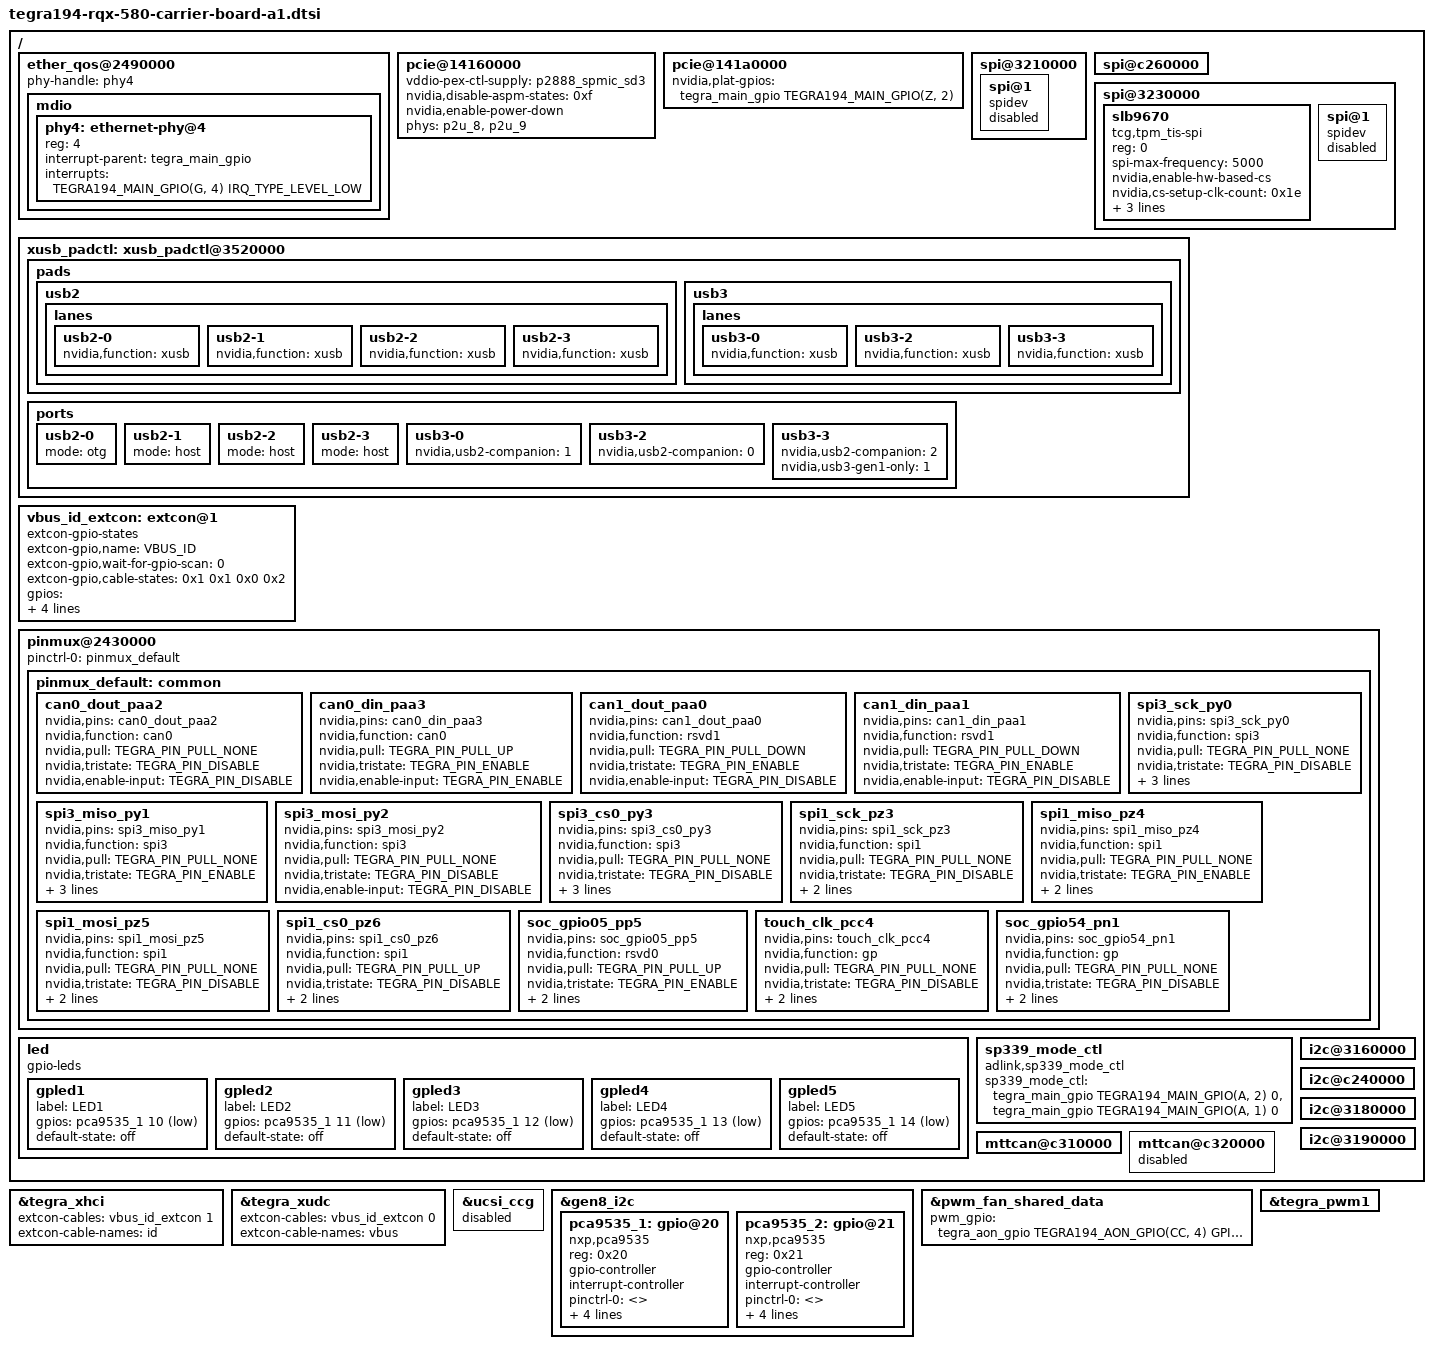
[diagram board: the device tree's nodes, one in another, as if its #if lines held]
/*
 * Copyright (c) 2020, ADLINKTECH CORPORATION.  All rights reserved.
 *
 * This program is free software; you can redistribute it and/or modify
 * it under the terms of the GNU General Public License as published by
 * the Free Software Foundation; version 2 of the License.
 *
 * This program is distributed in the hope that it will be useful, but WITHOUT
 * ANY WARRANTY; without even the implied warranty of MERCHANTABILITY or
 * FITNESS FOR A PARTICULAR PURPOSE.  See the GNU General Public License for
 * more details.
 */

#include <dt-bindings/gpio/tegra194-gpio.h>

/
{
    /* Etherent */
    ether_qos@2490000 {
		phy-handle = <&phy4>;
        mdio {
            phy4: ethernet-phy@4 {
				reg = <4>;
				interrupt-parent = <&tegra_main_gpio>;
				interrupts = <TEGRA194_MAIN_GPIO(G, 4) IRQ_TYPE_LEVEL_LOW>;				
			};
        };
    };

    /* <----- PCIE ----->  */
    pcie@14160000 { 
        status = "okay";

        vddio-pex-ctl-supply = <&p2888_spmic_sd3>;
        nvidia,disable-aspm-states = <0xf>;
        nvidia,enable-power-down;

        phys = <&p2u_8>, <&p2u_9>;
        phy-names = "pcie-p2u-0", "pcie-p2u-1";
    };
    
    //PCIe x16
    pcie@141a0000 { 
        status = "okay";

        nvidia,plat-gpios =
            <&tegra_main_gpio TEGRA194_MAIN_GPIO(Z, 2) GPIO_ACTIVE_HIGH    /* 3V3 */
               /*&tegra_main_gpio TEGRA194_MAIN_GPIO(A, 1) GPIO_ACTIVE_LOW  */ /* 12V */
            /*&tegra_main_gpio TEGRA194_MAIN_GPIO(Y, 4) GPIO_ACTIVE_HIGH */ /* I2C */
            >;
            //nvidia,disable-clock-request;
    };


    /* <----- SPI ----->  */
        // spi0
    spi@3210000 {
        status = "okay";
#if 0
        spi1_test: spi1_test@0 {  
            compatible = "spidev";
            reg = <0x0>;
            spi-max-frequency = <0x1312D00>;             
            status = "okay";
        };
#endif
            // spi0 CS.0 defined in : tegra194-p2888-0001-p2822-0000-common.dtsi
        /* SPI0 CS.1 */
        spi@1 {
            compatible = "spidev";
            status = "disabled";
        };
    };

    // spi1
    spi@c260000 {
        status = "okay";
    };

    // spi2
    spi@3230000 {
        status = "okay";
        slb9670: slb9670{   
            compatible = "tcg,tpm_tis-spi";
            reg = <0>; 
            #address-cells = <1>; 
            #size-cells = <0>; 
            spi-max-frequency = <5000>; 
            nvidia,enable-hw-based-cs;
            nvidia,cs-setup-clk-count = <0x1e>;
            nvidia,cs-hold-clk-count = <0x1e>;
            nvidia,rx-clk-tap-delay = <0x1f>;
            nvidia,tx-clk-tap-delau = <0x0>;
            status = "okay"; 
        };
        spi@1 {
            compatible = "spidev";
            status = "disabled";
        };
    };


#if TEGRA_XUSB_PADCONTROL_VERSION >= DT_VERSION_2

    xusb_padctl: xusb_padctl@3520000 {
        status = "okay";

        pads {
            usb2 {
                lanes {
                    usb2-0 {
                        nvidia,function = "xusb";
                        status = "okay";
                    };
                    usb2-1 {
                        nvidia,function = "xusb";
                        status = "okay";
                    };
                    usb2-2 {
                        nvidia,function = "xusb";
                        status = "okay";
                    };
                    usb2-3 {
                        nvidia,function = "xusb";
                        status = "okay";
                    };
                };
            };
            usb3 {
                lanes {
                    usb3-0 {
                            nvidia,function = "xusb";
                            status = "okay";
                    };
                    usb3-2 {
                            nvidia,function = "xusb";
                            status = "okay";
                    };
                    usb3-3 {
                            nvidia,function = "xusb";
                            status = "okay";
                    };
                };
            };
        };

        ports {
            usb2-0 {
                mode = "otg";
                status = "okay";
            };
            usb2-1 {
                mode = "host";
                status = "okay";
            };
            usb2-2 {
                mode = "host";
                status = "okay";
            };
            usb2-3 {
                mode = "host";
                status = "okay";
            };
            usb3-0 {
                nvidia,usb2-companion = <1>;
                status = "okay";
            };
            usb3-2 {
                nvidia,usb2-companion = <0>;
                status = "okay";
            };
            usb3-3 {
                nvidia,usb2-companion = <2>;
                nvidia,usb3-gen1-only= <1>;
                status = "okay";
            };
        };
    };
#endif

        vbus_id_extcon: extcon@1 { 
        compatible = "extcon-gpio-states";
        extcon-gpio,name = "VBUS_ID";
        extcon-gpio,wait-for-gpio-scan = <0>;

        extcon-gpio,cable-states = <0x1 0x1
                                    0x0 0x2>;
        gpios = <&tegra_main_gpio TEGRA194_MAIN_GPIO(Q, 0) 0>;
                        
#ifdef USE_VDD_5V_SATA
        vdd_5v_sata-supply = <&p2822_vdd_5v_sata>;
#endif
        //pin A62 for vbus detect pin and pin B55 for usb id pin

        /*
        extcon-gpio,cable-states = <0x3 0x0
                                    0x0 0x2
                                    0x1 0x2
                                    0x2 0x1>;
        gpios = <&tegra_aon_gpio TEGRA194_AON_GPIO(BB, 2) 0 
                 &tegra_main_gpio TEGRA194_MAIN_GPIO(Q, 0) 0>;
        */
        //extcon.h, EXTCON_NONE=0, EXTCON_USB=1, EXTCON_USB_HOST=2, 2019/04/24, Evan
        extcon-gpio,out-cable-names = <EXTCON_USB EXTCON_USB_HOST EXTCON_NONE>;
        #extcon-cells = <1>;
    };


    // pinmux for CAN0
    pinmux@2430000 {
        pinctrl-names = "default";
        pinctrl-0 = <&pinmux_default>;

        pinmux_default: common {
            /* <----- CAN pinmux ----->  */
            can0_dout_paa2 {
                nvidia,pins = "can0_dout_paa2";
                nvidia,function = "can0";
                nvidia,pull = <TEGRA_PIN_PULL_NONE>;
                nvidia,tristate = <TEGRA_PIN_DISABLE>;
                nvidia,enable-input = <TEGRA_PIN_DISABLE>;
            };

            can0_din_paa3 {
                nvidia,pins = "can0_din_paa3";
                nvidia,function = "can0";
                nvidia,pull = <TEGRA_PIN_PULL_UP>;
                nvidia,tristate = <TEGRA_PIN_ENABLE>;
                nvidia,enable-input = <TEGRA_PIN_ENABLE>;
            };

            can1_dout_paa0 {
                nvidia,pins = "can1_dout_paa0";
                nvidia,function = "rsvd1";
                nvidia,pull = <TEGRA_PIN_PULL_DOWN>;
                nvidia,tristate = <TEGRA_PIN_ENABLE>;
                nvidia,enable-input = <TEGRA_PIN_DISABLE>;
            };

            can1_din_paa1 {
                nvidia,pins = "can1_din_paa1";
                nvidia,function = "rsvd1";
                nvidia,pull = <TEGRA_PIN_PULL_DOWN>;
                nvidia,tristate = <TEGRA_PIN_ENABLE>;
                nvidia,enable-input = <TEGRA_PIN_DISABLE>;
            };

            /* <----- SPI3 pinmux for TPM SLM (/dev/spi2) ----->  */
            spi3_sck_py0 {
                nvidia,pins = "spi3_sck_py0";
                nvidia,function = "spi3";
                nvidia,pull = <TEGRA_PIN_PULL_NONE>;
                nvidia,tristate = <TEGRA_PIN_DISABLE>;
                nvidia,enable-input = <TEGRA_PIN_DISABLE>;
                nvidia,io-high-voltage = <TEGRA_PIN_DISABLE>;
                nvidia,lpdr = <TEGRA_PIN_DISABLE>;
            };
            spi3_miso_py1 {
                nvidia,pins = "spi3_miso_py1";
                nvidia,function = "spi3";
                nvidia,pull = <TEGRA_PIN_PULL_NONE>;
                nvidia,tristate = <TEGRA_PIN_ENABLE>;
                nvidia,enable-input = <TEGRA_PIN_ENABLE>;
                nvidia,io-high-voltage = <TEGRA_PIN_DISABLE>;
                nvidia,lpdr = <TEGRA_PIN_DISABLE>;
            };
            spi3_mosi_py2 {
                nvidia,pins = "spi3_mosi_py2";
                nvidia,function = "spi3";
                nvidia,pull = <TEGRA_PIN_PULL_NONE>;
                nvidia,tristate = <TEGRA_PIN_DISABLE>;
                nvidia,enable-input = <TEGRA_PIN_DISABLE>;
                //nvidia,io-high-voltage = <TEGRA_PIN_DISABLE>;
                //nvidia,lpdr = <TEGRA_PIN_DISABLE>;
            };
            spi3_cs0_py3 {
                nvidia,pins = "spi3_cs0_py3";
                nvidia,function = "spi3";
                nvidia,pull = <TEGRA_PIN_PULL_NONE>;
                nvidia,tristate = <TEGRA_PIN_DISABLE>;
                nvidia,enable-input = <TEGRA_PIN_DISABLE>;
                nvidia,io-high-voltage = <TEGRA_PIN_DISABLE>;
                nvidia,lpdr = <TEGRA_PIN_DISABLE>;
            };
            /* <----- SPI1 pinmux for 40pin headder (/dev/spi1) ----->  */
            spi1_sck_pz3 {
                nvidia,pins = "spi1_sck_pz3";
                nvidia,function = "spi1";
                nvidia,pull = <TEGRA_PIN_PULL_NONE>;
                nvidia,tristate = <TEGRA_PIN_DISABLE>;
                nvidia,enable-input = <TEGRA_PIN_DISABLE>;
                nvidia,lpdr = <TEGRA_PIN_DISABLE>;
            };

            spi1_miso_pz4 {
                nvidia,pins = "spi1_miso_pz4";
                nvidia,function = "spi1";
                nvidia,pull = <TEGRA_PIN_PULL_NONE>;
                nvidia,tristate = <TEGRA_PIN_ENABLE>;
                nvidia,enable-input = <TEGRA_PIN_ENABLE>;
                nvidia,lpdr = <TEGRA_PIN_DISABLE>;
            };

            spi1_mosi_pz5 {
                nvidia,pins = "spi1_mosi_pz5";
                nvidia,function = "spi1";
                nvidia,pull = <TEGRA_PIN_PULL_NONE>;
                nvidia,tristate = <TEGRA_PIN_DISABLE>;
                nvidia,enable-input = <TEGRA_PIN_DISABLE>;
                nvidia,lpdr = <TEGRA_PIN_DISABLE>;
            };

            spi1_cs0_pz6 {
                nvidia,pins = "spi1_cs0_pz6";
                nvidia,function = "spi1";
                nvidia,pull = <TEGRA_PIN_PULL_UP>;
                nvidia,tristate = <TEGRA_PIN_DISABLE>;
                nvidia,enable-input = <TEGRA_PIN_DISABLE>;
                nvidia,lpdr = <TEGRA_PIN_DISABLE>;
            };

            // C54 , pca9534-1 interrupt
            soc_gpio05_pp5 {
                nvidia,pins = "soc_gpio05_pp5";
                nvidia,function = "rsvd0";
                nvidia,pull = <TEGRA_PIN_PULL_UP>;
                nvidia,tristate = <TEGRA_PIN_ENABLE>;
                nvidia,enable-input = <TEGRA_PIN_ENABLE>;
                nvidia,lpdr = <TEGRA_PIN_DISABLE>;
            };

#if 0
                    // G55
            usb_vbus_en1_pz2 {
                nvidia,pins = "usb_vbus_en1_pz2";
                nvidia,function = "rsvd1";
                nvidia,pull = <TEGRA_PIN_PULL_NONE>;
                nvidia,tristate = <TEGRA_PIN_DISABLE>;
                nvidia,enable-input = <TEGRA_PIN_DISABLE>;
                nvidia,io-high-voltage = <TEGRA_PIN_DISABLE>;
                nvidia,lpdr = <TEGRA_PIN_DISABLE>;
            };

            // F54
            usb_vbus_en0_pz1 {
                nvidia,pins = "usb_vbus_en0_pz1";
                nvidia,function = "rsvd1";
                nvidia,pull = <TEGRA_PIN_PULL_NONE>;
                nvidia,tristate = <TEGRA_PIN_DISABLE>;
                nvidia,enable-input = <TEGRA_PIN_DISABLE>;
                nvidia,io-high-voltage = <TEGRA_PIN_DISABLE>;
                nvidia,lpdr = <TEGRA_PIN_DISABLE>;
            };
#endif
            // PWM
            touch_clk_pcc4 {
                nvidia,pins = "touch_clk_pcc4";
                nvidia,function = "gp";
                nvidia,pull = <TEGRA_PIN_PULL_NONE>;
                nvidia,tristate = <TEGRA_PIN_DISABLE>;
                nvidia,enable-input = <TEGRA_PIN_DISABLE>;
                nvidia,lpdr = <TEGRA_PIN_DISABLE>;
            };

            // PWM for 40pin header
            soc_gpio54_pn1 {
                nvidia,pins = "soc_gpio54_pn1";
                nvidia,function = "gp";
                nvidia,pull = <TEGRA_PIN_PULL_NONE>;
                nvidia,tristate = <TEGRA_PIN_DISABLE>;
                nvidia,enable-input = <TEGRA_PIN_DISABLE>;
                nvidia,lpdr = <TEGRA_PIN_DISABLE>;
            };
        };
    };

    led {  
        compatible = "gpio-leds";
        gpled1 { 
            label = "LED1"; /* USER_LED1 */
            gpios = <&pca9535_1 10 GPIO_ACTIVE_LOW>;
            default-state = "off";
        };
        gpled2 { 
            label = "LED2"; /* USER_LED2 */
            gpios = <&pca9535_1 11 GPIO_ACTIVE_LOW>;
            default-state = "off";
        };
        gpled3 { 
            label = "LED3"; /* USER_LED3 */
            gpios = <&pca9535_1 12 GPIO_ACTIVE_LOW>;
            default-state = "off";
        };
        gpled4 { 
            label = "LED4"; /* USER_LED4 */
            gpios = <&pca9535_1 13 GPIO_ACTIVE_LOW>;
            default-state = "off";
        };          

        gpled5 { 
            label = "LED5"; /* USER_LED6 */
            gpios = <&pca9535_1 14 GPIO_ACTIVE_LOW>;
            default-state = "off";
        };

#if 0  // default NI, LED6 connect to CARRIER_PWR_ON
        gpled6 { 
            label = "LED6"; /* USER_LED6 */
            gpios = <&pca9535_1 7 GPIO_ACTIVE_LOW>;
            default-state = "off";
        };       
#endif        
    };

    /* ROSCube-X RS232/485 MUX */
    sp339_mode_ctl:sp339_mode_ctl {
        compatible = "adlink,sp339_mode_ctl";
        sp339_mode_ctl = <&tegra_main_gpio TEGRA194_MAIN_GPIO(A, 2)  0>,
                         <&tegra_main_gpio TEGRA194_MAIN_GPIO(A, 1)  0>;

        status = "okay";
    };

    i2c@3160000 {
                    status = "okay";
    };
    i2c@c240000 {
                    status = "okay";
    };
    i2c@3180000 {
                    status = "okay";
    };
    i2c@3190000 {
                    status = "okay";
    };

    mttcan@c310000 {
            status = "okay";
    };

    mttcan@c320000 {
            status = "disabled";
    };

    /delete-node/ bluedroid_pm;
};

&tegra_xhci { 
    extcon-cables = <&vbus_id_extcon 1>;
    extcon-cable-names = "id";
    #extcon-cells = <1>;
};

&tegra_xudc { 
    extcon-cables = <&vbus_id_extcon 0>;
    extcon-cable-names = "vbus";
    #extcon-cells = <1>;
};

&ucsi_ccg { 
    status = "disabled";
};


&gen8_i2c {
    status = "okay";  
    pca9535_1: gpio@20 {  
       compatible = "nxp,pca9535";
       reg = <0x20>;
       gpio-controller;
       interrupt-controller;
       #gpio-cells = <2>;
       pinctrl-names = "default";
       pinctrl-0 = <>;         
       #interrupt-cells = <2>;
       interrupt-parent = <&tegra_main_gpio>;
       interrupts = <TEGRA194_MAIN_GPIO(P, 5) GPIO_ACTIVE_HIGH>;
       vcc-supply = <&battery_reg>;
       status = "okay";            
    };

    pca9535_2: gpio@21 {  
       compatible = "nxp,pca9535"; 
       reg = <0x21>;
       gpio-controller;
       interrupt-controller;
       #gpio-cells = <2>;
       pinctrl-names = "default";
       pinctrl-0 = <>;             
       #interrupt-cells = <2>;
       interrupt-parent = <&tegra_main_gpio>;
       interrupts = <TEGRA194_MAIN_GPIO(P, 6) GPIO_ACTIVE_HIGH>;
       vcc-supply = <&battery_reg>;
       status = "okay";
    };
};

&pwm_fan_shared_data {
    pwm_gpio = <&tegra_aon_gpio TEGRA194_AON_GPIO(CC, 4) GPIO_ACTIVE_HIGH>;
};

&tegra_pwm1 {
    status = "okay";
};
